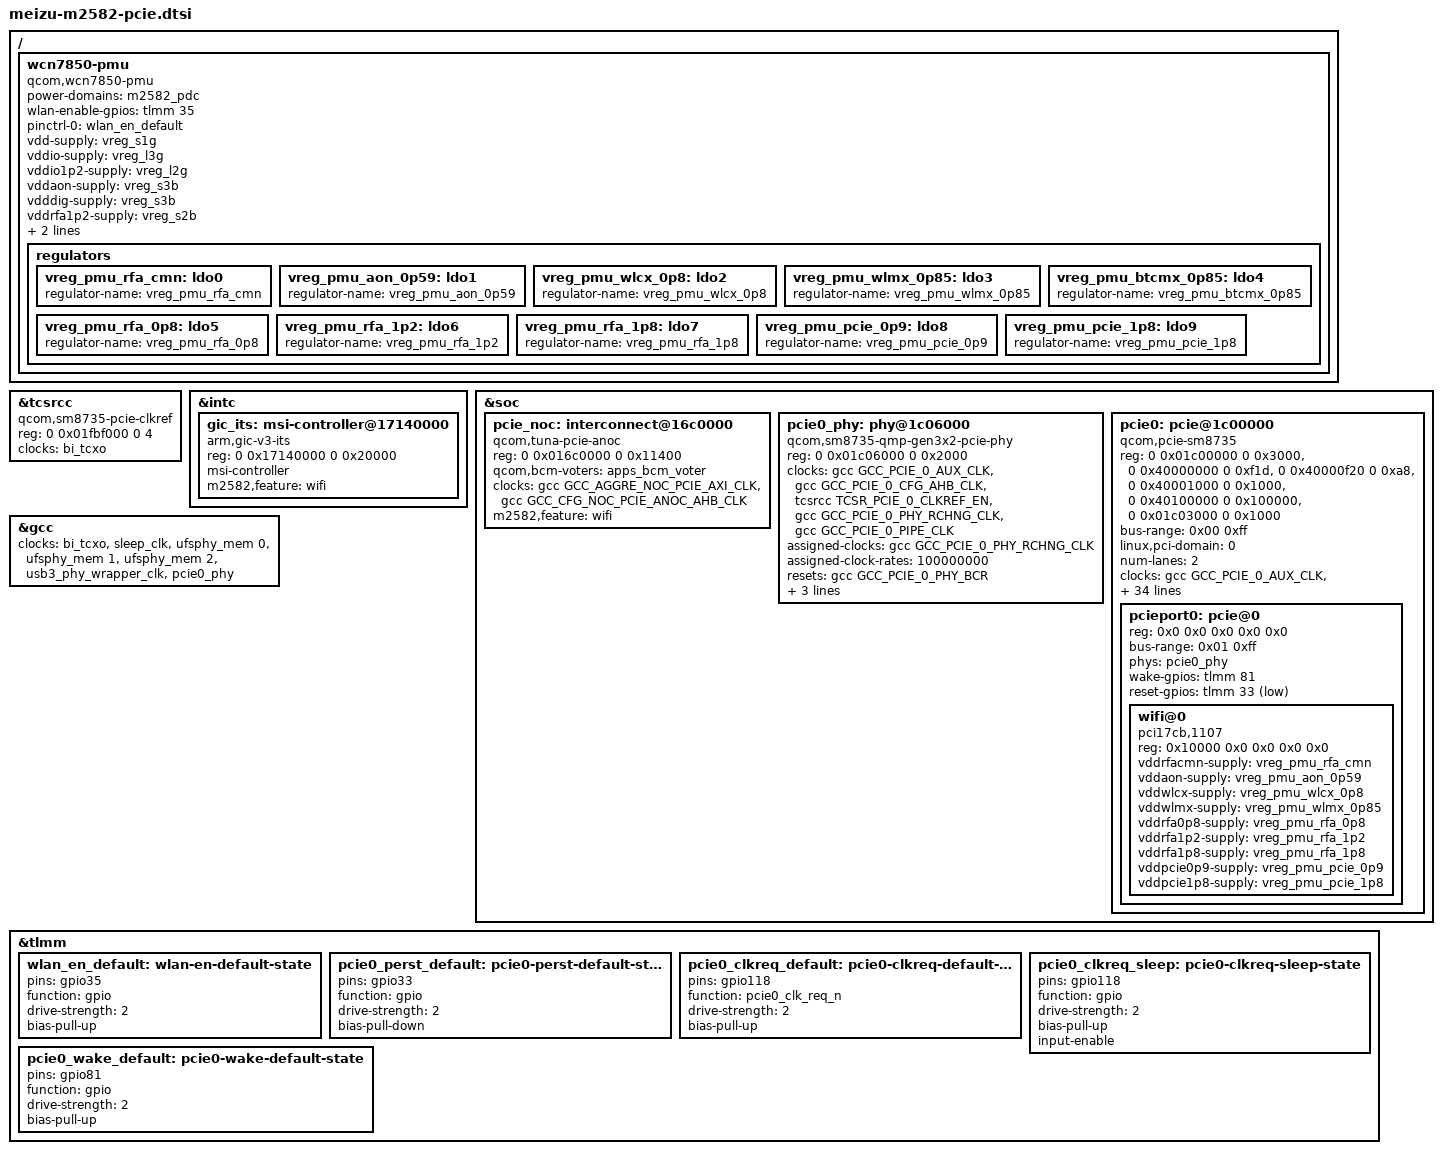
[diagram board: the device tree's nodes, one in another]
// SPDX-License-Identifier: BSD-3-Clause

/*
 * M2582 PCIe0 and WCN7750. Wiring, register windows and stream IDs follow
 * the phone's factory runtime DT (android-live-ON/live-fdt.dts).
 */

#include <dt-bindings/clock/qcom,gcc-tuna.h>
#include <dt-bindings/clock/qcom,tcsrcc-sun.h>
#include <dt-bindings/gpio/gpio.h>
#include <dt-bindings/interconnect/qcom,tuna.h>
#include <dt-bindings/interconnect/qcom,icc.h>
#include <dt-bindings/interrupt-controller/arm-gic.h>

/* Keep the protected USB/UFS TCSR registers outside this mapping. */
&tcsrcc {
	compatible = "qcom,sm8735-pcie-clkref";
	reg = <0 0x01fbf000 0 4>;
	clocks = <&bi_tcxo>;
	clock-names = "xo";
	status = "okay";
};

/ {
	wcn7850-pmu {
		compatible = "qcom,wcn7850-pmu";
		power-domains = <&m2582_pdc>;
		wlan-enable-gpios = <&tlmm 35 GPIO_ACTIVE_HIGH>;
		pinctrl-names = "default";
		pinctrl-0 = <&wlan_en_default>;

		vdd-supply = <&vreg_s1g>;

		vddio-supply = <&vreg_l3g>;
		vddio1p2-supply = <&vreg_l2g>;
		vddaon-supply = <&vreg_s3b>;
		vdddig-supply = <&vreg_s3b>;
		vddrfa1p2-supply = <&vreg_s2b>;
		vddrfa1p8-supply = <&vreg_s1b>;

		m2582,feature = "wifi";

		regulators {
			vreg_pmu_rfa_cmn: ldo0 {
				regulator-name = "vreg_pmu_rfa_cmn";
			};

			vreg_pmu_aon_0p59: ldo1 {
				regulator-name = "vreg_pmu_aon_0p59";
			};

			vreg_pmu_wlcx_0p8: ldo2 {
				regulator-name = "vreg_pmu_wlcx_0p8";
			};

			vreg_pmu_wlmx_0p85: ldo3 {
				regulator-name = "vreg_pmu_wlmx_0p85";
			};

			vreg_pmu_btcmx_0p85: ldo4 {
				regulator-name = "vreg_pmu_btcmx_0p85";
			};

			vreg_pmu_rfa_0p8: ldo5 {
				regulator-name = "vreg_pmu_rfa_0p8";
			};

			vreg_pmu_rfa_1p2: ldo6 {
				regulator-name = "vreg_pmu_rfa_1p2";
			};

			vreg_pmu_rfa_1p8: ldo7 {
				regulator-name = "vreg_pmu_rfa_1p8";
			};

			vreg_pmu_pcie_0p9: ldo8 {
				regulator-name = "vreg_pmu_pcie_0p9";
			};

			vreg_pmu_pcie_1p8: ldo9 {
				regulator-name = "vreg_pmu_pcie_1p8";
			};
		};
	};
};

&intc {
	gic_its: msi-controller@17140000 {
		compatible = "arm,gic-v3-its";
		reg = <0 0x17140000 0 0x20000>;
		msi-controller;
		#msi-cells = <1>;

		m2582,feature = "wifi";
	};
};

&soc {
	pcie_noc: interconnect@16c0000 {
		compatible = "qcom,tuna-pcie-anoc";
		reg = <0 0x016c0000 0 0x11400>;
		#interconnect-cells = <2>;
		qcom,bcm-voters = <&apps_bcm_voter>;
		clocks = <&gcc GCC_AGGRE_NOC_PCIE_AXI_CLK>,
			 <&gcc GCC_CFG_NOC_PCIE_ANOC_AHB_CLK>;
		clock-names = "aggre_noc_pcie_axi", "cfg_noc_pcie_anoc_ahb";

		m2582,feature = "wifi";
	};

	/* Factory PHY values/layout match the SM8550/SM8650 gen3x2 block. */
	pcie0_phy: phy@1c06000 {
		compatible = "qcom,sm8735-qmp-gen3x2-pcie-phy";
		reg = <0 0x01c06000 0 0x2000>;

		clocks = <&gcc GCC_PCIE_0_AUX_CLK>,
			 <&gcc GCC_PCIE_0_CFG_AHB_CLK>,
			 <&tcsrcc TCSR_PCIE_0_CLKREF_EN>,
			 <&gcc GCC_PCIE_0_PHY_RCHNG_CLK>,
			 <&gcc GCC_PCIE_0_PIPE_CLK>;
		clock-names = "aux",
			      "cfg_ahb",
			      "ref",
			      "rchng",
			      "pipe";

		assigned-clocks = <&gcc GCC_PCIE_0_PHY_RCHNG_CLK>;
		assigned-clock-rates = <100000000>;

		resets = <&gcc GCC_PCIE_0_PHY_BCR>;
		reset-names = "phy";

		power-domains = <&gcc GCC_PCIE_0_PHY_GDSC>;

		#clock-cells = <0>;
		clock-output-names = "pcie_0_pipe_clk";
		#phy-cells = <0>;

		m2582,feature = "wifi";
	};

	pcie0: pcie@1c00000 {
		compatible = "qcom,pcie-sm8735", "qcom,pcie-sm8550";
		device_type = "pci";

		reg = <0 0x01c00000 0 0x3000>,
		      <0 0x40000000 0 0xf1d>,
		      <0 0x40000f20 0 0xa8>,
		      <0 0x40001000 0 0x1000>,
		      <0 0x40100000 0 0x100000>,
		      <0 0x01c03000 0 0x1000>;
		reg-names = "parf", "dbi", "elbi", "atu", "config", "mhi";

		#address-cells = <3>;
		#size-cells = <2>;

		ranges = <0x01000000 0x00 0x40200000 0x00 0x40200000 0x00 0x100000>,
			 <0x02000000 0x00 0x40300000 0x00 0x40300000 0x00 0x3d00000>;
		bus-range = <0x00 0xff>;
		linux,pci-domain = <0>;

		num-lanes = <2>;

		clocks = <&gcc GCC_PCIE_0_AUX_CLK>,
			 <&gcc GCC_PCIE_0_CFG_AHB_CLK>,
			 <&gcc GCC_PCIE_0_MSTR_AXI_CLK>,
			 <&gcc GCC_PCIE_0_SLV_AXI_CLK>,
			 <&gcc GCC_PCIE_0_SLV_Q2A_AXI_CLK>,
			 <&gcc GCC_DDRSS_PCIE_SF_QTB_CLK>,
			 <&gcc GCC_AGGRE_NOC_PCIE_AXI_CLK>,
			 <&gcc GCC_CNOC_PCIE_SF_AXI_CLK>;
		clock-names = "aux",
			      "cfg",
			      "bus_master",
			      "bus_slave",
			      "slave_q2a",
			      "ddrss_sf_tbu",
			      "noc_aggr",
			      "cnoc_sf_axi";

		resets = <&gcc GCC_PCIE_0_BCR>;
		reset-names = "pci";

		power-domains = <&gcc GCC_PCIE_0_GDSC>;

		interconnects = <&pcie_noc MASTER_PCIE_0 QCOM_ICC_TAG_ALWAYS
				 &mc_virt SLAVE_EBI1 QCOM_ICC_TAG_ALWAYS>,
				<&gem_noc MASTER_APPSS_PROC QCOM_ICC_TAG_ALWAYS
				 &cnoc_main SLAVE_PCIE_0 QCOM_ICC_TAG_ALWAYS>;
		interconnect-names = "pcie-mem", "cpu-pcie";

		iommu-map = <0x0   &apps_smmu 0x1400 0x1>,
			    <0x100 &apps_smmu 0x1401 0x1>;

		msi-map = <0x0   &gic_its 0x1400 0x1>,
			  <0x100 &gic_its 0x1401 0x1>;

		interrupts = <GIC_SPI 140 IRQ_TYPE_LEVEL_HIGH>;
		interrupt-names = "global";
		#interrupt-cells = <1>;
		interrupt-map-mask = <0 0 0 0x7>;
		interrupt-map = <0 0 0 1 &intc 0 0 GIC_SPI 149 IRQ_TYPE_LEVEL_HIGH>,
				<0 0 0 2 &intc 0 0 GIC_SPI 150 IRQ_TYPE_LEVEL_HIGH>,
				<0 0 0 3 &intc 0 0 GIC_SPI 151 IRQ_TYPE_LEVEL_HIGH>,
				<0 0 0 4 &intc 0 0 GIC_SPI 152 IRQ_TYPE_LEVEL_HIGH>;

		dma-coherent;

		pinctrl-names = "default", "sleep";
		pinctrl-0 = <&pcie0_perst_default>, <&pcie0_clkreq_default>,
			    <&pcie0_wake_default>;
		pinctrl-1 = <&pcie0_perst_default>, <&pcie0_clkreq_sleep>,
			    <&pcie0_wake_default>;

		m2582,feature = "wifi";

		pcieport0: pcie@0 {
			device_type = "pci";
			reg = <0x0 0x0 0x0 0x0 0x0>;
			bus-range = <0x01 0xff>;
			#address-cells = <3>;
			#size-cells = <2>;
			ranges;

			phys = <&pcie0_phy>;

			wake-gpios = <&tlmm 81 GPIO_ACTIVE_HIGH>;
			reset-gpios = <&tlmm 33 GPIO_ACTIVE_LOW>;

			wifi@0 {
				compatible = "pci17cb,1107";
				reg = <0x10000 0x0 0x0 0x0 0x0>;

				vddrfacmn-supply = <&vreg_pmu_rfa_cmn>;
				vddaon-supply = <&vreg_pmu_aon_0p59>;
				vddwlcx-supply = <&vreg_pmu_wlcx_0p8>;
				vddwlmx-supply = <&vreg_pmu_wlmx_0p85>;
				vddrfa0p8-supply = <&vreg_pmu_rfa_0p8>;
				vddrfa1p2-supply = <&vreg_pmu_rfa_1p2>;
				vddrfa1p8-supply = <&vreg_pmu_rfa_1p8>;
				vddpcie0p9-supply = <&vreg_pmu_pcie_0p9>;
				vddpcie1p8-supply = <&vreg_pmu_pcie_1p8>;
			};
		};
	};
};

&gcc {
	clocks = <&bi_tcxo>, <&sleep_clk>,
		 <&ufsphy_mem 0>, <&ufsphy_mem 1>, <&ufsphy_mem 2>,
		 <&usb3_phy_wrapper_clk>,
		 <&pcie0_phy>;
	clock-names = "bi_tcxo", "sleep_clk", "ufs_phy_rx_symbol_0_clk",
		      "ufs_phy_rx_symbol_1_clk", "ufs_phy_tx_symbol_0_clk",
		      "usb3_phy_wrapper_gcc_usb30_pipe_clk",
		      "pcie_0_pipe_clk";
};

&tlmm {
	wlan_en_default: wlan-en-default-state {
		pins = "gpio35";
		function = "gpio";
		drive-strength = <2>;
		bias-pull-up;
	};

	pcie0_perst_default: pcie0-perst-default-state {
		pins = "gpio33";
		function = "gpio";
		drive-strength = <2>;
		bias-pull-down;
	};

	pcie0_clkreq_default: pcie0-clkreq-default-state {
		pins = "gpio118";
		function = "pcie0_clk_req_n";
		drive-strength = <2>;
		bias-pull-up;
	};

	pcie0_clkreq_sleep: pcie0-clkreq-sleep-state {
		pins = "gpio118";
		function = "gpio";
		drive-strength = <2>;
		bias-pull-up;
		input-enable;
	};

	pcie0_wake_default: pcie0-wake-default-state {
		pins = "gpio81";
		function = "gpio";
		drive-strength = <2>;
		bias-pull-up;
	};
};
